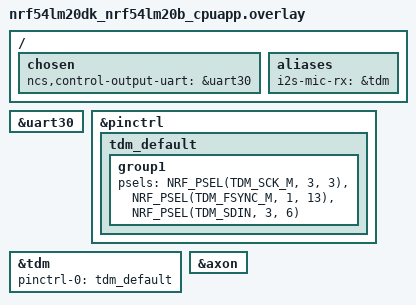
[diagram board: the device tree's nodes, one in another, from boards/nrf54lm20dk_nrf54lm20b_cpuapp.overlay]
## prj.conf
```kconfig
#
# Copyright (c) 2026 Nordic Semiconductor
#
# SPDX-License-Identifier: LicenseRef-Nordic-5-Clause
#

# nRF Edge AI
CONFIG_NRF_EDGEAI=y

# nRF Edge AI dependencies
CONFIG_NRF_AXON=y
CONFIG_NEWLIB_LIBC=y
CONFIG_FPU=y

# Size of interlayer buffer to fit model
CONFIG_NRF_AXON_INTERLAYER_BUFFER_SIZE=6700

# Size of psum buffer to fit model
CONFIG_NRF_AXON_PSUM_BUFFER_SIZE=0

# Peripherals
CONFIG_GPIO=y
CONFIG_I2S=y

# Enable logging and assert
CONFIG_LOG=y
CONFIG_CONSOLE=y
CONFIG_SERIAL=y
CONFIG_ASSERT=y

CONFIG_UART_ASYNC_API=y
CONFIG_MAIN_STACK_SIZE=4096
```

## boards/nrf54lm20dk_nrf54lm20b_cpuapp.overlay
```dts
/*
 * Copyright (c) 2026 Nordic Semiconductor ASA
 *
 * SPDX-License-Identifier: LicenseRef-Nordic-5-Clause
 *
 * INMP441 wiring:
 *   INMP441 SCK  -> DK pin 14 / P3.03  (TDM_SCK_M)
 *   INMP441 WS   -> DK pin 8  / P1.13  (TDM_FSYNC_M)
 *   INMP441 SD   -> DK pin 18 / P3.06  (TDM_SDIN)
 *   INMP441 VDD  -> 3V3
 *   INMP441 GND  -> GND
 *   INMP441 L/R  -> GND (left channel)
 */

 / {
	chosen {
		ncs,control-output-uart = &uart30;
	};

	aliases {
		i2s-mic-rx = &tdm;
	};
};

&uart30 {
	status = "okay";
};

&pinctrl {
	tdm_default: tdm_default {
		group1 {
			psels = <NRF_PSEL(TDM_SCK_M, 3, 3)>,
				<NRF_PSEL(TDM_FSYNC_M, 1, 13)>,
				<NRF_PSEL(TDM_SDIN, 3, 6)>;
		};
	};
};

&tdm {
	status = "okay";
	pinctrl-0 = <&tdm_default>;
	pinctrl-names = "default";
};

&axon {
	status = "okay";
};
```

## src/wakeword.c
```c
/*
 * Copyright (c) 2026 Nordic Semiconductor ASA
 *
 * SPDX-License-Identifier: LicenseRef-Nordic-5-Clause
 */

#include <stddef.h>
#include <stdint.h>

#include <zephyr/kernel.h>
#include <zephyr/logging/log.h>
#include <nrf_edgeai/nrf_edgeai.h>

#include "dmic.h"
#include "wakeword.h"
#include "nrf_edgeai_generated/nrf_edgeai_user_model.h"

LOG_MODULE_REGISTER(ww);

static nrf_edgeai_t *ww_model;

int ww_init(void)
{
    /*
     * IMPORTANT:
     * Use the generic generated alias from the current model bundle.
     * For your new custom model, this resolves to nrf_edgeai_user_model_94081().
     */
    ww_model = nrf_edgeai_user_model();
    __ASSERT_NO_MSG(ww_model);

    nrf_edgeai_err_t err = nrf_edgeai_init(ww_model);

    if (err) {
        LOG_ERR("Model initialization failed (err %d)", err);
        return -ENOENT;
    }

    return 0;
}

static bool ww_postprocess(void)
{
    static uint32_t ww_count;
    static uint32_t ww_history;
    static int64_t last_detect_time_ms;

    const float ww_threshold = CONFIG_WW_PROBABILITY_THRESHOLD / 1000.f;
    const int64_t now_ms = k_uptime_get();
    const int64_t cooldown_ms = 1200;

    const uint16_t predicted_class = ww_model->decoded_output.classif.predicted_class;
    const float class_probability =
        ww_model->decoded_output.classif.probabilities.p_f32[predicted_class];
    const bool ww_detected = class_probability > ww_threshold;

    const bool oldest_entry = (bool)(ww_history & BIT(CONFIG_WW_HISTORY_SIZE - 1));

    ww_count = ww_count + ww_detected - oldest_entry;
    ww_history = (ww_history << 1) | ww_detected;

    LOG_DBG("postprocess: count: %2u, probability: %f",
            ww_count, (double)class_probability);

    if (ww_count >= CONFIG_WW_COUNT_THRESHOLD) {
        ww_count = 0;
        ww_history = 0;

        if ((now_ms - last_detect_time_ms) < cooldown_ms) {
            return false;
        }

        last_detect_time_ms = now_ms;
        return true;
    }

    return false;
}

int ww_process(uint8_t *const audio_buffer, const uint16_t num_samples, bool *const ww_detected)
{
    __ASSERT_NO_MSG(audio_buffer);
    __ASSERT_NO_MSG(num_samples == nrf_edgeai_input_window_size(ww_model));
    __ASSERT_NO_MSG(ww_detected);

    nrf_edgeai_err_t err;

    err = nrf_edgeai_feed_inputs(ww_model, audio_buffer, num_samples);
    free_dmic_buffer(audio_buffer);

    if (err == NRF_EDGEAI_ERR_INPROGRESS) {
        return -EBUSY;
    } else if (err) {
        LOG_ERR("Failed to feed inputs (err %d)", err);
        return -EPERM;
    }

    err = nrf_edgeai_run_inference(ww_model);
    if (err == NRF_EDGEAI_ERR_INPROGRESS) {
        return -EBUSY;
    } else if (err) {
        LOG_ERR("Failed to run inference (err %d)", err);
        return -EPERM;
    }

    *ww_detected = ww_postprocess();

    return 0;
}
```
